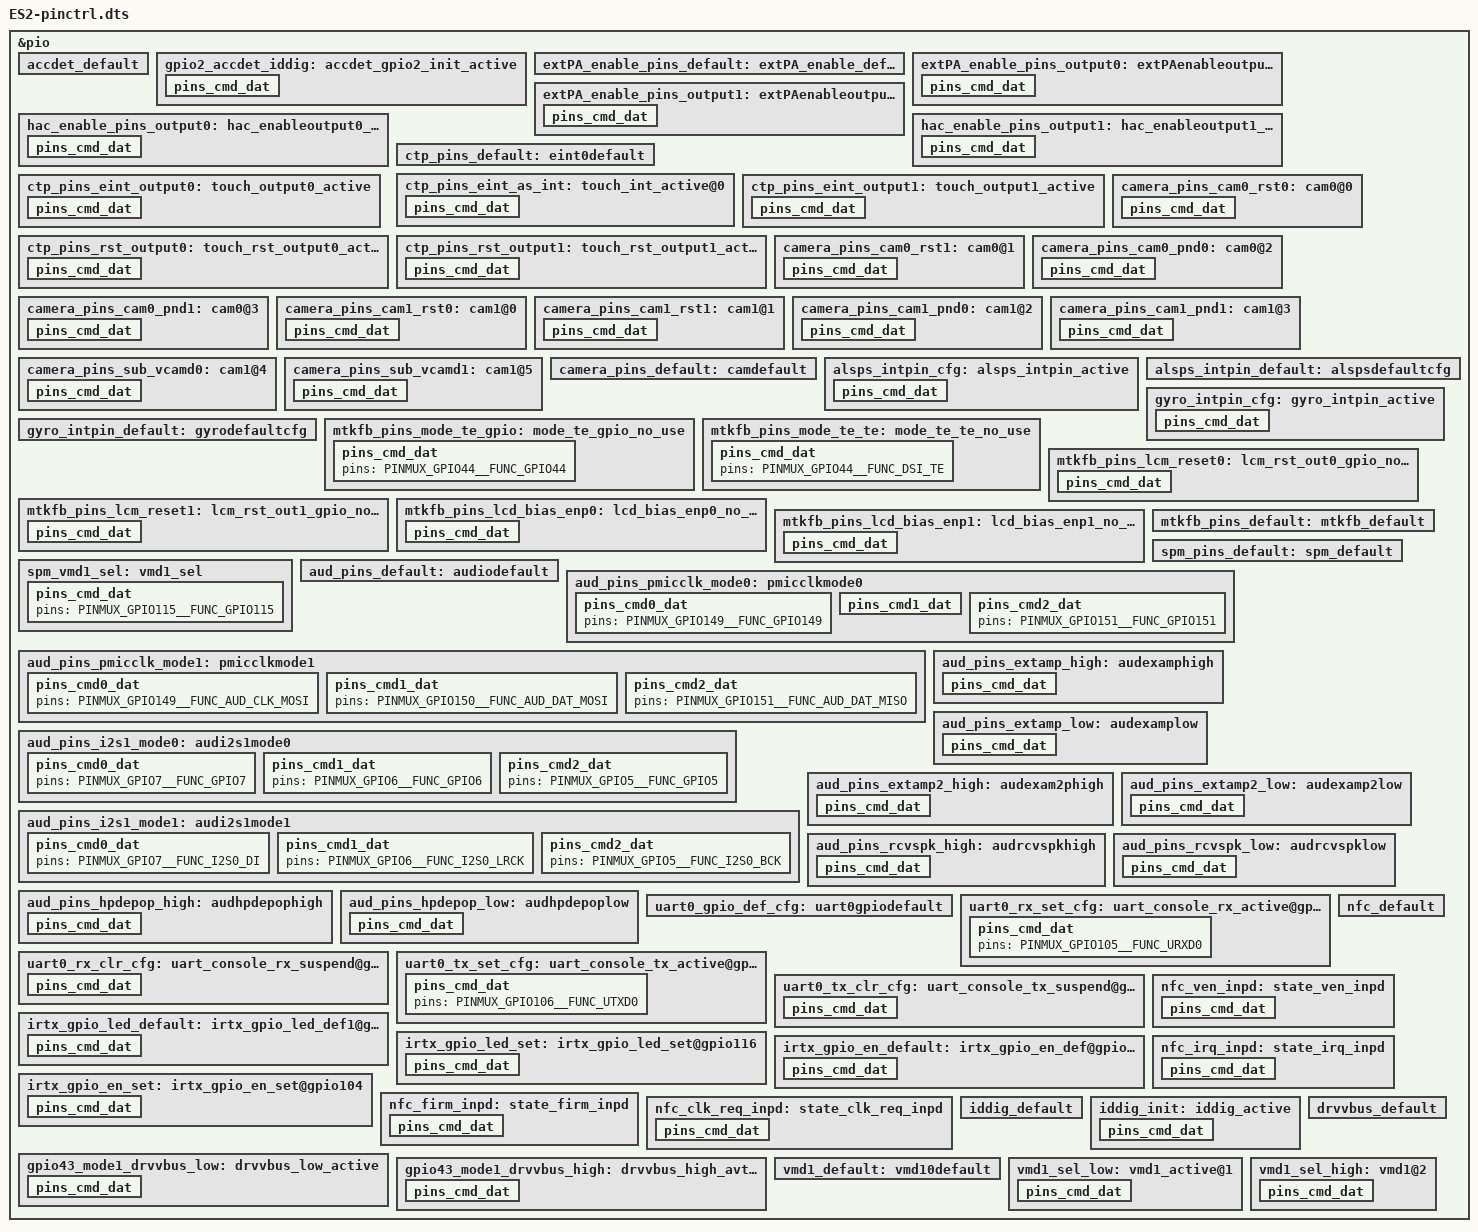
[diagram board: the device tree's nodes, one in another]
/*for ES2 PINCTRL*/

/*****************************************************************
*GPIO standardization  Area

*From:  	ES2.dts
*Notice:	When MTK release new code,pls check and sync this file
			carefully
******************************************************************/

/*ACCDET*/
&pio {
        accdet_default: accdet_default {
        };

        gpio2_accdet_iddig: accdet_gpio2_init_active {
                pins_cmd_dat {
                        pins = <PINMUX_GPIO2__FUNC_GPIO2>;
                        slew-rate = <0>;
                        bias-disable;
                };
        };

};

/* ext PA enable start */
&pio {
         extPA_enable_pins_default: extPA_enable_default {

         };

         extPA_enable_pins_output0: extPAenableoutput0_suspend {
                pins_cmd_dat {
                        pins = <PINMUX_GPIO24__FUNC_GPIO24>;
                        slew-rate = <1>; //output
                        output-low;
                };
        };

        extPA_enable_pins_output1: extPAenableoutput1_active {
                pins_cmd_dat {
                        pins = <PINMUX_GPIO24__FUNC_GPIO24>;
                        slew-rate = <1>;
                        output-high;
                };
        };
        hac_enable_pins_output0: hac_enableoutput0_suspend {
                pins_cmd_dat {
                        pins = <PINMUX_GPIO61__FUNC_GPIO61>;
                        slew-rate = <1>; //output
                        output-low;
                };
        };

        hac_enable_pins_output1: hac_enableoutput1_active {
                pins_cmd_dat {
                        pins = <PINMUX_GPIO61__FUNC_GPIO61>;
                        slew-rate = <1>;
                        output-high;
                };
        };
};


/*TOUCH*/
&pio {
        ctp_pins_default: eint0default {
        };
        ctp_pins_eint_as_int: touch_int_active@0 {
                pins_cmd_dat {
                        pins = <PINMUX_GPIO1__FUNC_GPIO1>;
                        slew-rate = <0>;
                        bias-disable;
                };
        };
        ctp_pins_eint_output0: touch_output0_active {
                pins_cmd_dat {
                        pins = <PINMUX_GPIO1__FUNC_GPIO1>;
                        slew-rate = <1>;
                        output-low;
                };
        };
        ctp_pins_eint_output1: touch_output1_active {
                pins_cmd_dat {
                        pins = <PINMUX_GPIO1__FUNC_GPIO1>;
                        slew-rate = <1>;
                        output-high;
                };
        };
        ctp_pins_rst_output0: touch_rst_output0_active {
                pins_cmd_dat {
                        pins = <PINMUX_GPIO10__FUNC_GPIO10>;
                        slew-rate = <1>;
                        output-low;
                };
        };
        ctp_pins_rst_output1: touch_rst_output1_active {
                pins_cmd_dat {
                        pins = <PINMUX_GPIO10__FUNC_GPIO10>;
                        slew-rate = <1>;
                        output-high;
                };
        };
};

/* CAMERA GPIO standardization */
&pio {
        camera_pins_cam0_rst0: cam0@0 {
            pins_cmd_dat {
                        pins = <PINMUX_GPIO110__FUNC_GPIO110>;
                        slew-rate = <1>; /*direction 0:in, 1:out*/
                        output-low;/*direction out used only. output_low or high*/
                };
        };
        camera_pins_cam0_rst1: cam0@1 {
            pins_cmd_dat {
                        pins = <PINMUX_GPIO110__FUNC_GPIO110>;
                        slew-rate = <1>;
                        output-high;
                };
        };
        camera_pins_cam0_pnd0: cam0@2 {
            pins_cmd_dat {
                        pins = <PINMUX_GPIO107__FUNC_GPIO107>;
                        slew-rate = <1>;
                        output-low;
                };
        };
        camera_pins_cam0_pnd1: cam0@3 {
            pins_cmd_dat {
                        pins = <PINMUX_GPIO107__FUNC_GPIO107>;
                        slew-rate = <1>;
                        output-high;
                };
        };
        camera_pins_cam1_rst0: cam1@0 {
            pins_cmd_dat {
                        pins = <PINMUX_GPIO111__FUNC_GPIO111>;
                        slew-rate = <1>; /*direction 0:in, 1:out*/
                        output-low;/*direction out used only. output_low or high*/
                };
        };
        camera_pins_cam1_rst1: cam1@1 {
            pins_cmd_dat {
                        pins = <PINMUX_GPIO111__FUNC_GPIO111>;
                        slew-rate = <1>;
                        output-high;
                };
        };
        camera_pins_cam1_pnd0: cam1@2 {
            pins_cmd_dat {
                        pins = <PINMUX_GPIO108__FUNC_GPIO108>;
                        slew-rate = <1>;
                        output-low;
                };
        };
        camera_pins_cam1_pnd1: cam1@3 {
            pins_cmd_dat {
                        pins = <PINMUX_GPIO108__FUNC_GPIO108>;
                        slew-rate = <1>;
                        output-high;
                };
        };
        camera_pins_sub_vcamd0: cam1@4 {
                pins_cmd_dat {
                        pins = <PINMUX_GPIO82__FUNC_GPIO82>;
                        slew-rate = <1>;
                        output-low;
                };
        };
        camera_pins_sub_vcamd1: cam1@5 {
                pins_cmd_dat {
                        pins = <PINMUX_GPIO82__FUNC_GPIO82>;
                        slew-rate = <1>;
                        output-high;
                };
        };
        /*camera_pins_cam_ldo_vcama_0: cam@vcama0 {
        };
        camera_pins_cam_ldo_vcama_1: cam@vcama1 {
        };*/
        camera_pins_default: camdefault {
        };

};

&pio {
        alsps_intpin_cfg: alsps_intpin_active {

                pins_cmd_dat {
                        pins = <PINMUX_GPIO6__FUNC_GPIO6>;
                        slew-rate = <0>;
                        bias-pull-up = <00>;
                };
        };

        alsps_intpin_default: alspsdefaultcfg {

        };

        gyro_intpin_cfg: gyro_intpin_active {

                pins_cmd_dat {
                        pins = <PINMUX_GPIO4__FUNC_GPIO4>;
                        slew-rate = <0>;
                        bias-pull-down = <00>;
                };
        };

        gyro_intpin_default: gyrodefaultcfg {

        };
};

/* DISPSYS GPIO standardization */
&pio {

        mtkfb_pins_mode_te_gpio: mode_te_gpio_no_use {
                pins_cmd_dat {
                        pins = <PINMUX_GPIO44__FUNC_GPIO44>;
                };
        };

        mtkfb_pins_mode_te_te: mode_te_te_no_use {
                pins_cmd_dat {
                        pins = <PINMUX_GPIO44__FUNC_DSI_TE>;
                };
        };

        mtkfb_pins_lcm_reset0: lcm_rst_out0_gpio_no_use {
                pins_cmd_dat {
                        pins = <PINMUX_GPIO158__FUNC_LCM_RST>;
                        slew-rate = <1>;
                        output-low;
                };
        };

        mtkfb_pins_lcm_reset1: lcm_rst_out1_gpio_no_use {
                pins_cmd_dat {
                        pins = <PINMUX_GPIO158__FUNC_LCM_RST>;
                        slew-rate = <1>;
                        output-high;
                };
        };

        mtkfb_pins_lcd_bias_enp0: lcd_bias_enp0_no_use {
                pins_cmd_dat {
                        pins = <PINMUX_GPIO12__FUNC_GPIO12>;
                        slew-rate = <1>;
                        output-low;
                };
        };

        mtkfb_pins_lcd_bias_enp1: lcd_bias_enp1_no_use {
                pins_cmd_dat {
                        pins = <PINMUX_GPIO12__FUNC_GPIO12>;
                        slew-rate = <1>;
                        output-high;
                };
        };

        mtkfb_pins_default: mtkfb_default {
        };
};

/* SPM GPIO standardization -- no use in ES2 */
&pio {
        spm_pins_default: spm_default {
        };

        spm_vmd1_sel: vmd1_sel {
                pins_cmd_dat {
                        pins = <PINMUX_GPIO115__FUNC_GPIO115>;
                };
        };

};

/* Audio GPIO standardization -- no use in ES2 */
&pio {
        aud_pins_default: audiodefault {
        };

        aud_pins_pmicclk_mode0: pmicclkmode0 {
                pins_cmd0_dat {
                        pins = <PINMUX_GPIO149__FUNC_GPIO149>;
                };
                pins_cmd1_dat {
                        pins = <PINMUX_GPIO150__FUNC_GPIO150>;
                        slew-rate = <0>;
                        bias-pull-up = <00>;
                };
                pins_cmd2_dat {
                        pins = <PINMUX_GPIO151__FUNC_GPIO151>;
                };
        };

        aud_pins_pmicclk_mode1: pmicclkmode1 {
                pins_cmd0_dat {
                        pins = <PINMUX_GPIO149__FUNC_AUD_CLK_MOSI>;
                };
                pins_cmd1_dat {
                        pins = <PINMUX_GPIO150__FUNC_AUD_DAT_MOSI>;
                };
                pins_cmd2_dat {
                        pins = <PINMUX_GPIO151__FUNC_AUD_DAT_MISO>;
                };
        };

        aud_pins_i2s1_mode0: audi2s1mode0 {
                pins_cmd0_dat {
                        pins = <PINMUX_GPIO7__FUNC_GPIO7>;
                };
                pins_cmd1_dat {
                        pins = <PINMUX_GPIO6__FUNC_GPIO6>;
                };
                pins_cmd2_dat {
                        pins = <PINMUX_GPIO5__FUNC_GPIO5>;
                };
        };

        aud_pins_i2s1_mode1: audi2s1mode1 {
                pins_cmd0_dat {
                        pins = <PINMUX_GPIO7__FUNC_I2S0_DI>;
                };
                pins_cmd1_dat {
                        pins = <PINMUX_GPIO6__FUNC_I2S0_LRCK>;
                };
                pins_cmd2_dat {
                        pins = <PINMUX_GPIO5__FUNC_I2S0_BCK>;
                };
        };


        aud_pins_extamp_high: audexamphigh {
                pins_cmd_dat {
                        pins = <PINMUX_GPIO115__FUNC_GPIO115>;
                        slew-rate = <1>;
                        output-high;
                };
        };

        aud_pins_extamp_low: audexamplow {
                pins_cmd_dat {
                        pins = <PINMUX_GPIO115__FUNC_GPIO115>;
                        slew-rate = <1>;
                        output-low;
                };
        };

        aud_pins_extamp2_high: audexam2phigh {
                pins_cmd_dat {
                        pins = <PINMUX_GPIO54__FUNC_GPIO54>;
                        slew-rate = <1>;
                        output-high;
                };
        };
        aud_pins_extamp2_low: audexamp2low {
                pins_cmd_dat {
                        pins = <PINMUX_GPIO54__FUNC_GPIO54>;
                        slew-rate = <1>;
                        output-low;
                };
        };

        aud_pins_rcvspk_high: audrcvspkhigh {
                pins_cmd_dat {
                        pins = <PINMUX_GPIO120__FUNC_GPIO120>;
                        slew-rate = <1>;
                        output-high;
                };
        };

        aud_pins_rcvspk_low: audrcvspklow {
                pins_cmd_dat {
                        pins = <PINMUX_GPIO120__FUNC_GPIO120>;
                        slew-rate = <1>;
                        output-low;
                };
        };

        aud_pins_hpdepop_high: audhpdepophigh {
                pins_cmd_dat {
                        pins = <PINMUX_GPIO24__FUNC_GPIO24>;
                        slew-rate = <1>;
                        output-high;
                };
        };

        aud_pins_hpdepop_low: audhpdepoplow {
                pins_cmd_dat {
                        pins = <PINMUX_GPIO24__FUNC_GPIO24>;
                        slew-rate = <1>;
                        output-low;
                };
        };
};

&pio {
        /* UART GPIO Settings - Start */
        /* UART0: rx set, rx clear, tx clear, tx clear*/
        uart0_gpio_def_cfg:uart0gpiodefault {

        };
        uart0_rx_set_cfg:uart_console_rx_active@gpio105 {
                pins_cmd_dat {
                        pins = <PINMUX_GPIO105__FUNC_URXD0>;
                };
        };
        uart0_rx_clr_cfg:uart_console_rx_suspend@gpio105  {
                pins_cmd_dat {
                        pins = <PINMUX_GPIO105__FUNC_GPIO105>;
                        slew-rate = <1>;
                        output-high;
                };
        };
        uart0_tx_set_cfg:uart_console_tx_active@gpio106  {
                pins_cmd_dat {
                        pins = <PINMUX_GPIO106__FUNC_UTXD0>;
                };
        };
        uart0_tx_clr_cfg:uart_console_tx_suspend@gpio106  {
                pins_cmd_dat {
                        pins = <PINMUX_GPIO106__FUNC_GPIO106>;
                        slew-rate = <1>;
                        output-high;
                };
        };
};/* UART GPIO end */

/* no use in ES2 */
&pio {
        /* IRTX GPIO Settings -Start */
        /* default: GPIO0, output, high */
        irtx_gpio_led_default:irtx_gpio_led_def1@gpio116 {
                pins_cmd_dat {
                        pins = <PINMUX_GPIO116__FUNC_GPIO116>;
                        slew-rate = <1>;
                        bias-disable;
                        output-low;
                        input-schmitt-enable = <0>;
                };
        };

        irtx_gpio_led_set:irtx_gpio_led_set@gpio116 {
                pins_cmd_dat {
                        pins = <PINMUX_GPIO116__FUNC_PWM_C>;
                        slew-rate = <1>;
                        output-high;
                };
        };

        irtx_gpio_en_default:irtx_gpio_en_def@gpio104 {
                pins_cmd_dat {
                        pins = <PINMUX_GPIO104__FUNC_GPIO104>;
                        slew-rate = <1>;
                        bias-disable;
                        output-low;
                        input-schmitt-enable = <0>;
                };
        };

        irtx_gpio_en_set:irtx_gpio_en_set@gpio104 {
                pins_cmd_dat {
                        pins = <PINMUX_GPIO104__FUNC_GPIO104>;
                        slew-rate = <1>;
                        output-high;
                };
        };


};

/* NFC GPIO standardization -- no use in ES2*/
&pio {
        nfc_default: nfc_default {

        };

        /*nfc_ven_high: state_ven_high {
                pins_cmd_dat {
                        pins = <PINMUX_GPIO28__FUNC_GPIO28>;
                        slew-rate = <1>;
                        output-high;
                };
        };

        nfc_ven_low: state_ven_low {
                pins_cmd_dat {
                        pins = <PINMUX_GPIO28__FUNC_GPIO28>;
                        slew-rate = <1>;
                        output-low;
                };
        };

        nfc_eint_high: state_eint_high {
                pins_cmd_dat {
                        pins = <PINMUX_GPIO27__FUNC_GPIO27>;
                        slew-rate = <1>;
                        output-high;
                };
        };

        nfc_eint_low: state_eint_low {
                pins_cmd_dat {
                        pins = <PINMUX_GPIO27__FUNC_GPIO27>;
                        slew-rate = <1>;
                        output-low;
                };
        };

        nfc_irq_init: state_irq_init {
                pins_cmd_dat {
                        pins = <PINMUX_GPIO26__FUNC_GPIO26>;
                        slew-rate = <0>;
                        bias-pull-down = <00>;
                };
        };*/
	nfc_ven_inpd: state_ven_inpd {
                pins_cmd_dat {
                        pins = <PINMUX_GPIO99__FUNC_GPIO99>;
                        slew-rate = <0>;
                        bias-pull-down = <00>;
                };
        };

	nfc_irq_inpd: state_irq_inpd {
                pins_cmd_dat {
                        pins = <PINMUX_GPIO26__FUNC_GPIO26>;
                        slew-rate = <0>;
                        bias-pull-down = <00>;
                };
        };

	nfc_firm_inpd: state_firm_inpd {
                pins_cmd_dat {
                        pins = <PINMUX_GPIO28__FUNC_GPIO28>;
                        slew-rate = <0>;
                        bias-pull-down = <00>;
                };
        };

	nfc_clk_req_inpd: state_clk_req_inpd {
                pins_cmd_dat {
                        pins = <PINMUX_GPIO27__FUNC_GPIO27>;
                        slew-rate = <0>;
                        bias-pull-down = <00>;
                };
        };

};

&pio {
        iddig_default: iddig_default {
        };

        iddig_init: iddig_active {
                pins_cmd_dat {
                        pins = <PINMUX_GPIO23__FUNC_IDDIG>;
                        slew-rate = <0>;
                        bias-pull-up = <00>;
                };
        };
};

&pio {
        drvvbus_default: drvvbus_default {
        };

        gpio43_mode1_drvvbus_low: drvvbus_low_active {
                pins_cmd_dat {
                        pins = <PINMUX_GPIO43__FUNC_USB_DRVVBUS>;
                        slew-rate = <1>;
                        output-low;
                };
        };

        gpio43_mode1_drvvbus_high: drvvbus_high_avtive {
                pins_cmd_dat {
                        pins = <PINMUX_GPIO43__FUNC_USB_DRVVBUS>;
                        slew-rate = <1>;
                        output-high;
                };
        };
};

&pio {
        vmd1_default: vmd10default {
        };

        vmd1_sel_low: vmd1_active@1 {
                pins_cmd_dat {
                        pins = <PINMUX_GPIO115__FUNC_GPIO115>;
                        slew-rate = <1>;
                        output-low;
                };
        };

        vmd1_sel_high: vmd1@2 {/* no use this func*/
                pins_cmd_dat {
                        pins = <PINMUX_GPIO115__FUNC_GPIO115>;
                        slew-rate = <1>;
                        output-high;
                };
        };
};

